# WLR089U0 register map
Vendor: Microchip Technology; Series: WLR089; File version: 0
CPU: CM0+ r0p0, selectable endian, no MPU, no FPU, VTOR, 2 interrupt priority bits
Registers are 32-bit, read-write, reset 0x0 unless marked. A register's access mark holds for its fields unless they carry their own. Offsets are from the block's base; [hi:lo] are bit positions; {n}, {i} and the like mark numbered series; 'fields as' and 'values as' point back to an identical list.

## PTC — Peripheral Touch Controller
Base 0x43001400; register names take the prefix PTC_

## RSTC — Reset Controller
Base 0x40000800; register names take the prefix RSTC_
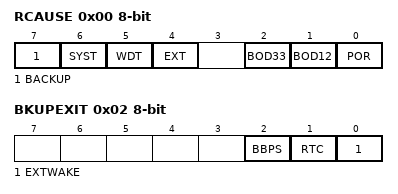
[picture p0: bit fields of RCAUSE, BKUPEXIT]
0x00 RCAUSE 8-bit ro — Reset Cause
  [7] BACKUP — Backup Reset
  [6] SYST — System Reset Request
  [5] WDT — Watchdog Reset
  [4] EXT — External Reset
  [2] BOD33 — Brown Out 33 Detector Reset
  [1] BOD12 — Brown Out 12 Detector Reset
  [0] POR — Power On Reset
0x02 BKUPEXIT 8-bit ro — Backup Exit Source
  [2] BBPS — Battery Backup Power Switch
  [1] RTC — Real Timer Counter Interrupt
  [0] EXTWAKE — External Wakeup
0x04 WKDBCONF 8-bit — Wakeup Debounce Configuration
  [4:0] WKDBCNT — Wakeup Debounce Counter
    0=OFF (No debouncing.Input pin is low or high level sensitive depending on its WKPOLx bit.); 1=2CK32 (Input pin shall be active for at least two 32kHz clock period.); 2=3CK32 (Input pin shall be active for at least three 32kHz clock period.); 3=32CK32 (Input pin shall be active for at least 32 32kHz clock period.); 4=512CK32 (Input pin shall be active for at least 512 32kHz clock period.); 5=4096CK32 (Input pin shall be active for at least 4096 32kHz clock period.); 6=32768CK32 (Input pin shall be active for at least 32768 32kHz clock period.)
0x08 WKPOL 16-bit — Wakeup Polarity
  [7:0] WKPOL
0x0C WKEN 16-bit — Wakeup Enable
  [7:0] WKEN
0x10 WKCAUSE 16-bit — Wakeup Cause

## TRNG — True Random Generator
Base 0x42003800; register names take the prefix TRNG_
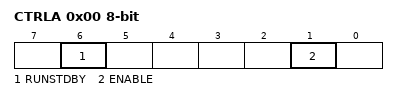
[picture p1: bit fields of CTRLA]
0x00 CTRLA 8-bit — Control A
  [6] RUNSTDBY — Run in Standby
  [1] ENABLE
0x04 EVCTRL 8-bit — Event Control
  [0] DATARDYEO — Data Ready Event Output
0x08 INTENCLR 8-bit — Interrupt Enable Clear
  [0] DATARDY — Data Ready Interrupt Enable
0x09 INTENSET 8-bit — Interrupt Enable Set
  [0] DATARDY — Data Ready Interrupt Enable
0x0A INTFLAG 8-bit — Interrupt Flag Status and Clear
  [0] DATARDY — Data Ready Interrupt Flag
0x20 DATA ro — Output Data

## WDT — Watchdog Timer
Base 0x40001C00; register names take the prefix WDT_
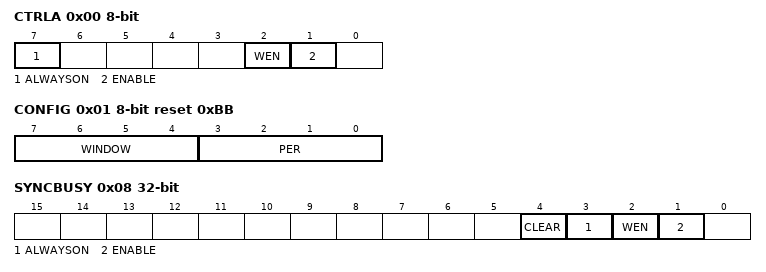
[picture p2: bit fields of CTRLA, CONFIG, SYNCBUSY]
0x00 CTRLA 8-bit — Control
  [7] ALWAYSON
  [2] WEN — Watchdog Timer Window Mode Enable
  [1] ENABLE
0x01 CONFIG 8-bit reset 0xBB — Configuration
  [7:4] WINDOW — Window Mode Time-Out Period
    0=CYC8 (8 clock cycles); 1=CYC16 (16 clock cycles); 2=CYC32 (32 clock cycles); 3=CYC64 (64 clock cycles); 4=CYC128 (128 clock cycles); 5=CYC256 (256 clock cycles); 6=CYC512 (512 clock cycles); 7=CYC1024 (1024 clock cycles); 8=CYC2048 (2048 clock cycles); 9=CYC4096 (4096 clock cycles); 10=CYC8192 (8192 clock cycles); 11=CYC16384 (16384 clock cycles)
  [3:0] PER — Time-Out Period
    values as WINDOW
0x02 EWCTRL 8-bit reset 0xB — Early Warning Interrupt Control
  [3:0] EWOFFSET — Early Warning Interrupt Time Offset
    values as CONFIG.WINDOW
0x04 INTENCLR 8-bit — Interrupt Enable Clear
  [0] EW — Early Warning Interrupt Enable
0x05 INTENSET 8-bit — Interrupt Enable Set
  [0] EW — Early Warning Interrupt Enable
0x06 INTFLAG 8-bit — Interrupt Flag Status and Clear
  [0] EW — Early Warning
0x08 SYNCBUSY ro — Synchronization Busy
  [4] CLEAR — Clear Busy
  [3] ALWAYSON — Always-On Busy
  [2] WEN — Window Enable Busy
  [1] ENABLE — Enable Busy
0x0C CLEAR 8-bit wo
  [7:0] CLEAR — Watchdog Clear
    165=KEY (Clear Key)

## NVIC — Nested Vectored Interrupt Controller
Base 0xE000E100; register names take the prefix NVIC_
0x00 ISER — Interrupt Set Enable Register
  [28:0] SETENA — Interrupt set enable bits
0x80 ICER — Interrupt Clear Enable Register
  [28:0] CLRENA — Interrupt clear-enable bits
0x100 ISPR — Interrupt Set Pending Register
  [28:0] SETPEND — Interrupt set-pending bits
0x180 ICPR — Interrupt Clear Pending Register
  [28:0] CLRPEND — Interrupt clear-pending bits
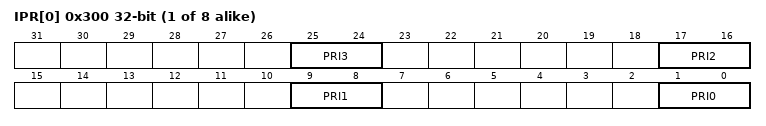
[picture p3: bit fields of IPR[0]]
{0x300+4i} IPR[{i}] (i=0..7) — Interrupt Priority Register n
  [8n+1:8n] PRI{n} (n=0..3) — Priority of interrupt n
